VERSION ""

NS_ :

BS_:

BU_:

BO_ 1025 Precharge_Timeout: 1 Vector__XXX
	SG_ Motor_Precharge_Timeout : 0|1@1+ (1,0) [0|1] "" Vector__XXX
	SG_ Array_Precharge_Timeout : 1|1@1+ (1,0) [0|0] "" Vector__XXX

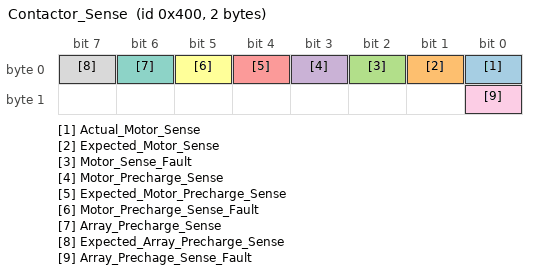
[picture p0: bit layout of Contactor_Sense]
BO_ 1024 Contactor_Sense: 2 Vector__XXX
	SG_ Actual_Motor_Sense : 0|1@1+ (1,0) [0|1] "" Vector__XXX
	SG_ Expected_Motor_Sense : 1|1@1+ (1,0) [0|0] "" Vector__XXX
	SG_ Motor_Sense_Fault : 2|1@1+ (1,0) [0|1] "" Vector__XXX
	SG_ Motor_Precharge_Sense : 3|1@1+ (1,0) [0|1] "" Vector__XXX
	SG_ Expected_Motor_Precharge_Sense : 4|1@1+ (1,0) [0|1] "" Vector__XXX
	SG_ Motor_Precharge_Sense_Fault : 5|1@1+ (1,0) [0|1] "" Vector__XXX
	SG_ Array_Precharge_Sense : 6|1@1+ (1,0) [0|1] "" Vector__XXX
	SG_ Expected_Array_Precharge_Sense : 7|1@1+ (1,0) [0|1] "" Vector__XXX
	SG_ Array_Prechage_Sense_Fault : 8|1@1+ (1,0) [0|1] "" Vector__XXX

BA_DEF_ BO_  "VFrameFormat" ENUM  "StandardCAN","ExtendedCAN","reserved","J1939PG";
BA_DEF_  "DatabaseVersion" STRING ;
BA_DEF_  "BusType" STRING ;
BA_DEF_  "ProtocolType" STRING ;
BA_DEF_  "DatabaseCompiler" STRING ;
BA_DEF_DEF_  "VFrameFormat" "J1939PG";
BA_DEF_DEF_  "DatabaseVersion" "DEMO PLUS";
BA_DEF_DEF_  "BusType" "";
BA_DEF_DEF_  "ProtocolType" "";
BA_DEF_DEF_  "DatabaseCompiler" "";
BA_ "ProtocolType" "J1939";
BA_ "BusType" "CAN";
BA_ "DatabaseCompiler" "CSS ELECTRONICS (WWW.CSSELECTRONICS.COM)";
BA_ "DatabaseVersion" "1.0.0";
